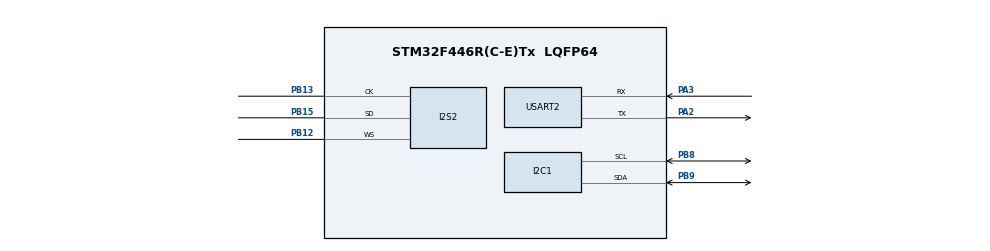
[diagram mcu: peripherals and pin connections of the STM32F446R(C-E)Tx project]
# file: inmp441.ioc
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Dma.Request0=SPI2_RX
Dma.SPI2_RX.0.Direction=DMA_PERIPH_TO_MEMORY
Dma.SPI2_RX.0.FIFOMode=DMA_FIFOMODE_DISABLE
Dma.SPI2_RX.0.Instance=DMA1_Stream3
Dma.SPI2_RX.0.MemDataAlignment=DMA_MDATAALIGN_HALFWORD
Dma.SPI2_RX.0.MemInc=DMA_MINC_ENABLE
Dma.SPI2_RX.0.Mode=DMA_CIRCULAR
Dma.SPI2_RX.0.PeriphDataAlignment=DMA_PDATAALIGN_HALFWORD
Dma.SPI2_RX.0.PeriphInc=DMA_PINC_DISABLE
Dma.SPI2_RX.0.Priority=DMA_PRIORITY_LOW
I2C1.I2C_Mode=I2C_Fast
I2S2.AudioFreq=I2S_AUDIOFREQ_16K
I2S2.DataFormat=I2S_DATAFORMAT_32B
I2S2.ErrorAudioFreq=-0.26 %
I2S2.FullDuplexMode=I2S_FULLDUPLEXMODE_DISABLE
I2S2.Instance=SPI$Index
I2S2.Mode=I2S_MODE_MASTER_RX
I2S2.RealAudioFreq=15.957 KHz
I2S2.VirtualMode=I2S_MODE_MASTER
Mcu.Family=STM32F4
Mcu.Name=STM32F446R(C-E)Tx
Mcu.Package=LQFP64
NVIC.DMA1_Stream3_IRQn=true\:0\:0\:false\:false\:true\:false\:true\:true
NVIC.PriorityGroup=NVIC_PRIORITYGROUP_4
PA2.Mode=Asynchronous
PA2.Signal=USART2_TX
PA3.Mode=Asynchronous
PA3.Signal=USART2_RX
PB12.Mode=Half_Duplex_Master
PB12.Signal=I2S2_WS
PB13.Mode=Half_Duplex_Master
PB13.Signal=I2S2_CK
PB15.Mode=Half_Duplex_Master
PB15.Signal=I2S2_SD
PB8.Mode=I2C
PB8.Signal=I2C1_SCL
PB9.Mode=I2C
PB9.Signal=I2C1_SDA
ProjectManager.HeapSize=0x200
ProjectManager.StackSize=0x1000
ProjectManager.TargetToolchain=STM32CubeIDE
RCC.CortexFreq_Value=16000000
RCC.USBFreq_Value=96000000
RCC.VCOOutputFreq_Value=192000000
USART2.VirtualMode=VM_ASYNC
board=custom

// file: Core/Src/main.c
/* USER CODE BEGIN Header */
/**
  ******************************************************************************
  * @file           : main.c
  * @brief          : Main program body
  ******************************************************************************
  * @attention
  *
  * Copyright (c) 2026 STMicroelectronics.
  * All rights reserved.
  *
  * This software is licensed under terms that can be found in the LICENSE file
  * in the root directory of this software component.
  * If no LICENSE file comes with this software, it is provided AS-IS.
  *
  ******************************************************************************
  */
/* USER CODE END Header */
#include "main.h"

/* USER CODE BEGIN Includes */
#include "app.h"
/* USER CODE END Includes */

/* USER CODE BEGIN PD */
#define BTN_Pin       GPIO_PIN_13 /* B1, el boton azul de la Nucleo: activo en bajo */
#define BTN_GPIO_Port GPIOC
/* USER CODE END PD */

I2C_HandleTypeDef hi2c1;

I2S_HandleTypeDef hi2s2;
DMA_HandleTypeDef hdma_spi2_rx;

UART_HandleTypeDef huart2;

void SystemClock_Config(void);
static void MX_GPIO_Init(void);
static void MX_DMA_Init(void);
static void MX_I2S2_Init(void);
static void MX_USART2_UART_Init(void);
static void MX_I2C1_Init(void);

int main(void)
{

  /* MCU Configuration--------------------------------------------------------*/

  /* Reset of all peripherals, Initializes the Flash interface and the Systick. */
  HAL_Init();

  /* Configure the system clock */
  SystemClock_Config();

  /* Initialize all configured peripherals */
  MX_GPIO_Init();
  MX_DMA_Init();
  MX_I2S2_Init();
  MX_USART2_UART_Init();
  MX_I2C1_Init();
  /* USER CODE BEGIN 2 */
  appFSM_init();
  /* USER CODE END 2 */

  /* Infinite loop */
  while (1)
  {

    /* USER CODE BEGIN 3 */
    appFSM_update();
  }
  /* USER CODE END 3 */
}

void SystemClock_Config(void)
{
  RCC_OscInitTypeDef RCC_OscInitStruct = {0};
  RCC_ClkInitTypeDef RCC_ClkInitStruct = {0};

  /** Macro to configure the PLL multiplication factor
  */
  __HAL_RCC_PLL_PLLM_CONFIG(16);

  /** Macro to configure the PLL clock source
  */
  __HAL_RCC_PLL_PLLSOURCE_CONFIG(RCC_PLLSOURCE_HSI);

  /** Configure the main internal regulator output voltage
  */
  __HAL_RCC_PWR_CLK_ENABLE();
  __HAL_PWR_VOLTAGESCALING_CONFIG(PWR_REGULATOR_VOLTAGE_SCALE3);

  /** Initializes the RCC Oscillators according to the specified parameters
  * in the RCC_OscInitTypeDef structure.
  */
  RCC_OscInitStruct.OscillatorType = RCC_OSCILLATORTYPE_HSI;
  RCC_OscInitStruct.HSIState = RCC_HSI_ON;
  RCC_OscInitStruct.HSICalibrationValue = RCC_HSICALIBRATION_DEFAULT;
  RCC_OscInitStruct.PLL.PLLState = RCC_PLL_NONE;
  RCC_OscInitStruct.PLL.PLLSource = RCC_PLLSOURCE_HSI;
  if (HAL_RCC_OscConfig(&RCC_OscInitStruct) != HAL_OK)
  {
    Error_Handler();
  }

  /** Initializes the CPU, AHB and APB buses clocks
  */
  RCC_ClkInitStruct.ClockType = RCC_CLOCKTYPE_HCLK|RCC_CLOCKTYPE_SYSCLK
                              |RCC_CLOCKTYPE_PCLK1|RCC_CLOCKTYPE_PCLK2;
  RCC_ClkInitStruct.SYSCLKSource = RCC_SYSCLKSOURCE_HSI;
  RCC_ClkInitStruct.AHBCLKDivider = RCC_SYSCLK_DIV1;
  RCC_ClkInitStruct.APB1CLKDivider = RCC_HCLK_DIV1;
  RCC_ClkInitStruct.APB2CLKDivider = RCC_HCLK_DIV1;

  if (HAL_RCC_ClockConfig(&RCC_ClkInitStruct, FLASH_LATENCY_0) != HAL_OK)
  {
    Error_Handler();
  }
}

static void MX_I2S2_Init(void)
{

  hi2s2.Instance = SPI2;
  hi2s2.Init.Mode = I2S_MODE_MASTER_RX;
  hi2s2.Init.Standard = I2S_STANDARD_PHILIPS;
  hi2s2.Init.DataFormat = I2S_DATAFORMAT_32B;
  hi2s2.Init.MCLKOutput = I2S_MCLKOUTPUT_DISABLE;
  hi2s2.Init.AudioFreq = I2S_AUDIOFREQ_16K;
  hi2s2.Init.CPOL = I2S_CPOL_LOW;
  hi2s2.Init.ClockSource = I2S_CLOCK_PLL;
  hi2s2.Init.FullDuplexMode = I2S_FULLDUPLEXMODE_DISABLE;
  if (HAL_I2S_Init(&hi2s2) != HAL_OK)
  {
    Error_Handler();
  }

}

static void MX_I2C1_Init(void)
{

  hi2c1.Instance = I2C1;
  hi2c1.Init.ClockSpeed = 100000;
  hi2c1.Init.DutyCycle = I2C_DUTYCYCLE_2;
  hi2c1.Init.OwnAddress1 = 0;
  hi2c1.Init.AddressingMode = I2C_ADDRESSINGMODE_7BIT;
  hi2c1.Init.DualAddressMode = I2C_DUALADDRESS_DISABLE;
  hi2c1.Init.OwnAddress2 = 0;
  hi2c1.Init.GeneralCallMode = I2C_GENERALCALL_DISABLE;
  hi2c1.Init.NoStretchMode = I2C_NOSTRETCH_DISABLE;
  if (HAL_I2C_Init(&hi2c1) != HAL_OK)
  {
    Error_Handler();
  }

}

static void MX_USART2_UART_Init(void)
{

  huart2.Instance = USART2;
  huart2.Init.BaudRate = 115200;
  huart2.Init.WordLength = UART_WORDLENGTH_8B;
  huart2.Init.StopBits = UART_STOPBITS_1;
  huart2.Init.Parity = UART_PARITY_NONE;
  huart2.Init.Mode = UART_MODE_TX_RX;
  huart2.Init.HwFlowCtl = UART_HWCONTROL_NONE;
  huart2.Init.OverSampling = UART_OVERSAMPLING_16;
  if (HAL_UART_Init(&huart2) != HAL_OK)
  {
    Error_Handler();
  }

}

static void MX_DMA_Init(void)
{

  /* DMA controller clock enable */
  __HAL_RCC_DMA1_CLK_ENABLE();

  /* DMA interrupt init */
  /* DMA1_Stream3_IRQn interrupt configuration */
  HAL_NVIC_SetPriority(DMA1_Stream3_IRQn, 0, 0);
  HAL_NVIC_EnableIRQ(DMA1_Stream3_IRQn);

}

static void MX_GPIO_Init(void)
{
  GPIO_InitTypeDef GPIO_InitStruct = {0};

  /* GPIO Ports Clock Enable */
  __HAL_RCC_GPIOA_CLK_ENABLE();
  __HAL_RCC_GPIOB_CLK_ENABLE();

  /* USER CODE BEGIN MX_GPIO_Init_2 */
  /* B1 no esta en el .ioc: se configura aca */
  __HAL_RCC_GPIOC_CLK_ENABLE();
  GPIO_InitStruct.Pin = BTN_Pin;
  GPIO_InitStruct.Mode = GPIO_MODE_INPUT;
  GPIO_InitStruct.Pull = GPIO_NOPULL; /* la Nucleo trae pull-up externo */
  HAL_GPIO_Init(BTN_GPIO_Port, &GPIO_InitStruct);

  /* USER CODE END MX_GPIO_Init_2 */
}

void Error_Handler(void)
{
  __disable_irq();
  while (1)
  {
  }
}
